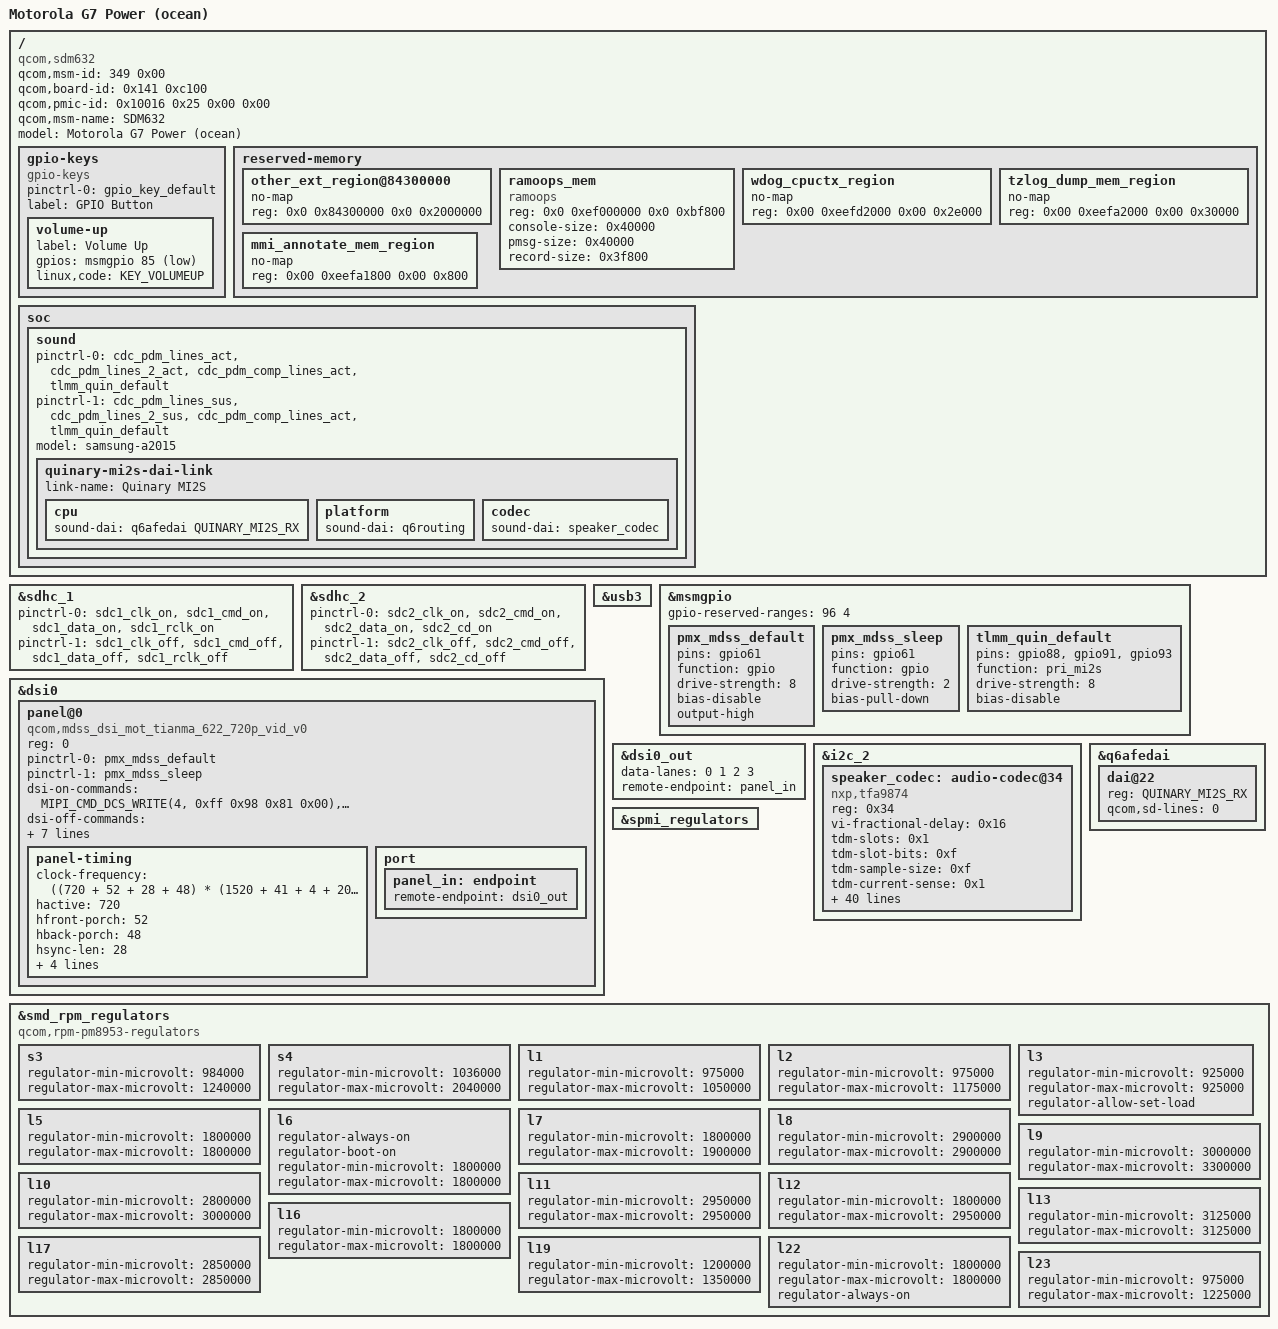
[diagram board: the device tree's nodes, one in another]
// SPDX-License-Identifier: GPL-2.0-only

/dts-v1/;

#include "sdm632.dtsi"
#include "pm8953.dtsi"
#include <dt-bindings/gpio/gpio.h>
#include <dt-bindings/display/mipi-dsi-generic.h>

/ {
	qcom,msm-id = <349 0x00>;
	qcom,board-id = <0x141 0xc100>;
	qcom,pmic-id = <0x10016 0x25 0x00 0x00>;
	qcom,msm-name = "SDM632";
	model = "Motorola G7 Power (ocean)";
	compatible = "qcom,sdm632", "qcom,msm8953";

	gpio-keys {
		compatible = "gpio-keys";

		pinctrl-names = "default";
		pinctrl-0 = <&gpio_key_default>;

		label = "GPIO Button";

		volume-up {
			label = "Volume Up";
			gpios = <&msmgpio 85 GPIO_ACTIVE_LOW>;
			linux,code = <KEY_VOLUMEUP>;
		};
	};

	reserved-memory {
		#address-cells = <2>;
		#size-cells = <2>;
		ranges;

		/delete-node/other_ext_region@85b00000;

		other_ext_region@84300000 {
			no-map;
			reg = <0x0 0x84300000 0x0 0x2000000>;
		};

		ramoops_mem {
			compatible = "ramoops";
			reg = <0x0 0xef000000 0x0 0xbf800>;
			console-size = <0x40000>;
			pmsg-size = <0x40000>;
			record-size = <0x3f800>;
		};

		wdog_cpuctx_region {
			no-map;
			reg = <0x00 0xeefd2000 0x00 0x2e000>;
		};

		tzlog_dump_mem_region {
			no-map;
			reg = <0x00 0xeefa2000 0x00 0x30000>;
		};

		mmi_annotate_mem_region {
			no-map;
			reg = <0x00 0xeefa1800 0x00 0x800>;
		};
	};

	soc {
		sound {
			status = "okay";

			pinctrl-names = "default", "sleep";
			pinctrl-0 = <&cdc_pdm_lines_act &cdc_pdm_lines_2_act &cdc_pdm_comp_lines_act &tlmm_quin_default>;
			pinctrl-1 = <&cdc_pdm_lines_sus &cdc_pdm_lines_2_sus &cdc_pdm_comp_lines_act &tlmm_quin_default>;
			model = "samsung-a2015";

			quinary-mi2s-dai-link {
				link-name = "Quinary MI2S";
				cpu {
					sound-dai = <&q6afedai QUINARY_MI2S_RX>;
				};

				platform {
					sound-dai = <&q6routing>;
				};

				codec {
					sound-dai = <&speaker_codec>;
				};
			};
		};
	};
};

&sdhc_1 {
	status = "okay";
	pinctrl-names = "default", "sleep";
	pinctrl-0 = <&sdc1_clk_on &sdc1_cmd_on &sdc1_data_on  &sdc1_rclk_on>;
	pinctrl-1 = <&sdc1_clk_off &sdc1_cmd_off &sdc1_data_off &sdc1_rclk_off>;
};

&sdhc_2 {
	status = "okay";
	pinctrl-names = "default", "sleep";
	pinctrl-0 = <&sdc2_clk_on &sdc2_cmd_on &sdc2_data_on &sdc2_cd_on>;
	pinctrl-1 = <&sdc2_clk_off &sdc2_cmd_off &sdc2_data_off &sdc2_cd_off>;
};

&usb3 {
	status = "okay";
};

&msmgpio {
	gpio-reserved-ranges = <96 4>;

	pmx_mdss_default: pmx_mdss_default {
		pins = "gpio61";
		function = "gpio";
		drive-strength = <8>;
		bias-disable;
		output-high;
	};

	pmx_mdss_sleep: pmx_mdss_sleep {
		pins = "gpio61";
		function = "gpio";
		drive-strength = <2>;
		bias-pull-down;
	};

	tlmm_quin_default: tlmm_quin_default {
		pins = "gpio88", "gpio91", "gpio93";
		function = "pri_mi2s";
		drive-strength = <8>;
		bias-disable;
	};
};

&dsi0 {
	panel@0 {
		compatible = "qcom,mdss_dsi_mot_tianma_622_720p_vid_v0", "panel-mipi-dsi-generic";
		reg = <0>;

		pinctrl-names = "default", "sleep";
		pinctrl-0 = <&pmx_mdss_default>;
		pinctrl-1 = <&pmx_mdss_sleep>;

		dsi-on-commands = MIPI_CMD_DCS_WRITE(4, 0xff 0x98 0x81 0x00),
		                  MIPI_CMD_DCS_WRITE(3, MIPI_CMD_DCS_SET_DISPLAY_BRIGHTNESS 0x0c 0xcc),
		                  MIPI_CMD_DCS_WRITE(2, MIPI_CMD_DCS_WRITE_CONTROL_DISPLAY 0x24),
		                  MIPI_CMD_DCS_WRITE(2, MIPI_CMD_DCS_WRITE_POWER_SAVE 0x01),
		                  MIPI_CMD_DCS_WRITE(1, MIPI_CMD_DCS_EXIT_SLEEP_MODE),
		                  MIPI_CMD_DELAY_MS(60),
		                  MIPI_CMD_DCS_WRITE(1, MIPI_CMD_DCS_SET_DISPLAY_ON),
		                  MIPI_CMD_DCS_WRITE(4, 0xff 0x98 0x81 0x03),
		                  MIPI_CMD_DCS_WRITE(2, 0x83 0x20),
		                  MIPI_CMD_DCS_WRITE(2, 0x84 0x02),
		                  MIPI_CMD_DCS_WRITE(2, 0xbc 0x08),
		                  MIPI_CMD_DCS_WRITE(4, 0xff 0x98 0x81 0x06),
		                  MIPI_CMD_DCS_WRITE(2, 0x06 0xc4),
		                  MIPI_CMD_DCS_WRITE(4, 0xff 0x98 0x81 0x00);
		dsi-off-commands = MIPI_CMD_DCS_WRITE(1, MIPI_CMD_DCS_SET_DISPLAY_OFF),
		                   MIPI_CMD_DELAY_MS(20),
		                   MIPI_CMD_DCS_WRITE(1, MIPI_CMD_DCS_ENTER_SLEEP_MODE),
		                   MIPI_CMD_DELAY_MS(120);
		dsi-format = <MIPI_GENERIC_DSI_FMT_RGB888>;
		dsi-lanes = <4>;
		dsi-mode = <(MIPI_GENERIC_DSI_MODE_VIDEO
			    |MIPI_GENERIC_DSI_MODE_VIDEO_BURST
			    |MIPI_GENERIC_DSI_CLOCK_NON_CONTINUOUS
			    |MIPI_GENERIC_DSI_MODE_LPM)>;

		panel-width-mm = <68>;
		panel-height-mm = <146>;

		panel-timing {
			clock-frequency = <((720 + 52 + 28 + 48) * (1520 + 41 + 4 + 20) * 60)>;

			hactive = <720>;
			hfront-porch = <52>;
			hback-porch = <48>;
			hsync-len = <28>;

			vactive = <1520>;
			vfront-porch = <41>;
			vback-porch = <20>;
			vsync-len = <4>;
		};

		port {
			panel_in: endpoint {
				remote-endpoint = <&dsi0_out>;
			};
		};
	};
};

&dsi0_out {
	data-lanes = <0 1 2 3>;
	remote-endpoint = <&panel_in>;
};

/*&dsi_phy0 {
	vddio-supply = <&pm8953_l6>;
};*/

&i2c_2 {
	status = "ok";

	speaker_codec: audio-codec@34 {
		compatible = "nxp,tfa9874";
		reg = <0x34>;

		vi-fractional-delay = <0x16>;
		tdm-slots = <0x1>;
		tdm-slot-bits = <0xf>;
		tdm-sample-size = <0xf>;
		tdm-current-sense = <0x1>;
		tdm-voltage-sense = <0x1>;
		tdm-sink1-enable = <0x0>;
		tdm-speaker-dcdc-slot = <0x0>;
		tdm-dcdc-slot = <0x1>;
		tdm-current-sense-slot = <0x1>;
		tdm-voltage-sense-slot = <0x0>;
		bypass-hpf = <0x0>;
		amplifier-gain = <0xbe>;
		bypass-lowpower = <0x1>;
		sel-pwm-delay-src = <0x0>;
		pwm-delay = <0x1>;
		ctrl-attl = <0xf>;
		tdm-speaker-gain = <0x6>;
		lpm1-mode = <0x1>;
		tdm-source-mapping = <0x2>;
		tdm-sense-a-val = <0x1>;
		tdm-sense-b-val = <0x2>;
		cursense-comp-delay = <0x5>;
		enable-cursense-comp = <0x1>;
		pwms-clip-lvl = <0x1>;
		slope-compensation-current = <0x3>;
		dcdcoff-mode = <0x0>;
		boost-track = <0x1>;
		boost-hold-time = <0x8>;
		second-boost-voltage = <0x3f>;
		first-boost-trip-lvl = <0x9>;
		ignore-flag-voutcomp86 = <0x0>;
		boost-trip-lvl-track = <0xd>;
		enable-trip-hyst = <0x1>;
		select-clk-cs = <0x0>;
		cs-ktemp = <0x19>;
		cs-ktemp2 = <0x1e>;
		cs-adc-nortz = <0x0>;
		cs-adc-offset = <0x4>;
		cs-classd-trans-skip = <0x1>;
		cs-inn-short = <0x0>;
		cs-inp-short = <0x0>;
		volsense-pwm-selection = <0x2>;
		bypass-otp = <0x0>;
		test-boost-ocp = <0x0>;

		#sound-dai-cells = <0>;
		status = "okay";
	};
};

&q6afedai {
	dai@22 {
		reg = <QUINARY_MI2S_RX>;
		qcom,sd-lines = <0>;
	};
};

&spmi_regulators {
	status = "okay";
};

&smd_rpm_regulators {
	compatible = "qcom,rpm-pm8953-regulators";

#if 0
	s1_level {
		status = "okay";
		regulator-min-microvolt = <0x10>;
		regulator-max-microvolt = <0x180>;
	};
#endif
	s3 {
		status = "okay";
		regulator-min-microvolt = <984000>;
		regulator-max-microvolt = <1240000>;
	};
	s4 {
		status = "okay";
		regulator-min-microvolt = <1036000>;
		regulator-max-microvolt = <2040000>;
	};
	l1 {
		status = "okay";
		regulator-min-microvolt = <975000>;
		regulator-max-microvolt = <1050000>;
	};
	l2 {
		status = "okay";
		regulator-min-microvolt = <975000>;
		regulator-max-microvolt = <1175000>;
	};
	l3 {
		status = "okay";
		regulator-min-microvolt = <925000>;
		regulator-max-microvolt = <925000>;
		regulator-allow-set-load;
	};
	l5 {
		status = "okay";
		regulator-min-microvolt = <1800000>;
		regulator-max-microvolt = <1800000>;
	};
	l6 { //WARNING: some ocean models use l22 instead
		status = "okay";
		regulator-always-on;
		regulator-boot-on;
		regulator-min-microvolt = <1800000>;
		regulator-max-microvolt = <1800000>;
		};
	l7 {
		status = "okay";
		regulator-min-microvolt = <1800000>;
		regulator-max-microvolt = <1900000>;
	};
	l8 {
		status = "okay";
		regulator-min-microvolt = <2900000>;
		regulator-max-microvolt = <2900000>;
	};
	l9 {
		status = "okay";
		regulator-min-microvolt = <3000000>;
		regulator-max-microvolt = <3300000>;
	};
	l10 {
		status = "okay";
		regulator-min-microvolt = <2800000>;
		regulator-max-microvolt = <3000000>;
	};
	l11 {
		status = "okay";
		regulator-min-microvolt = <2950000>;
		regulator-max-microvolt = <2950000>;
	};
	l12 {
		status = "okay";
		regulator-min-microvolt = <1800000>;
		regulator-max-microvolt = <2950000>;
	};
	l13 {
		status = "okay";
		regulator-min-microvolt = <3125000>;
		regulator-max-microvolt = <3125000>;
	};
	l16 {
		status = "okay";
		regulator-min-microvolt = <1800000>;
		regulator-max-microvolt = <1800000>;
	};
	l17 {
		status = "okay";
		regulator-min-microvolt = <2850000>;
		regulator-max-microvolt = <2850000>;
	};
	l19 {
		status = "okay";
		regulator-min-microvolt = <1200000>;
		regulator-max-microvolt = <1350000>;
	};
	l22 {
		status = "okay";
		regulator-min-microvolt = <1800000>;
		regulator-max-microvolt = <1800000>;
		regulator-always-on;
	};
	l23 {
		status = "okay";
		regulator-min-microvolt = <975000>;
		regulator-max-microvolt = <1225000>;
	};
};
